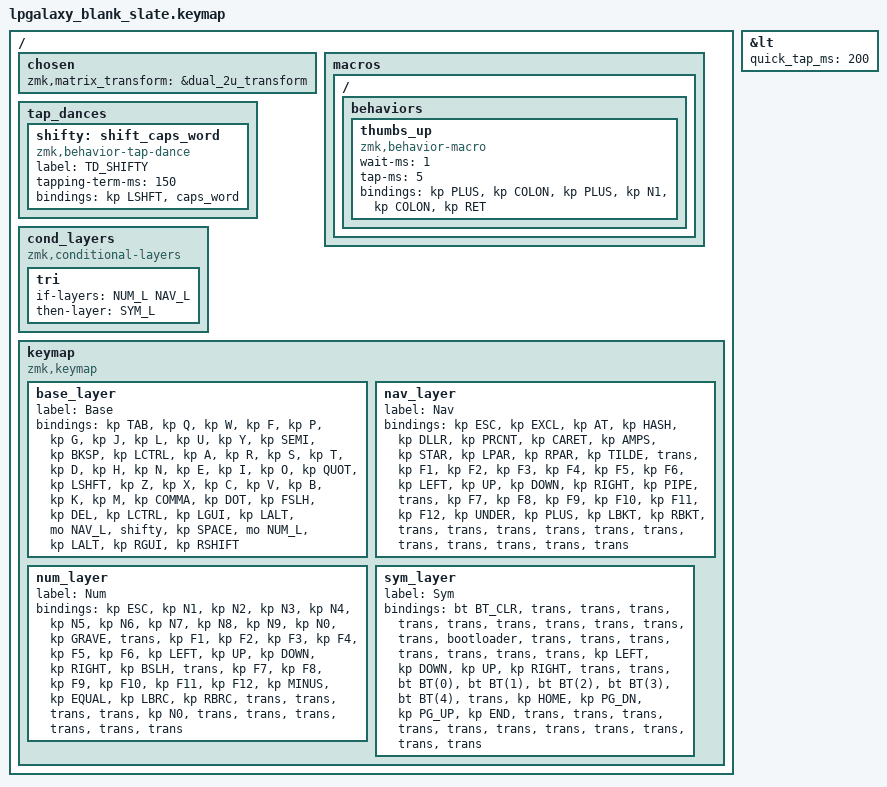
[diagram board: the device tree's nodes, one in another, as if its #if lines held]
/*
 * Copyright (c) 2022 Pete Johanson
 *
 * SPDX-License-Identifier: MIT
 */

#include <behaviors.dtsi>
#include <dt-bindings/zmk/keys.h>
#include <dt-bindings/zmk/bt.h>
#include <dt-bindings/zmk/outputs.h>

#define QWERTY_BASE 1

#define TBLE_ORTHO   1
// #define TBLE_MIT     1
// #define TBLE_DUAL_2U 1

#define NAV_L 1
#define NUM_L 2
#define SYM_L 3

// Using layer taps on thumbs, having quick tap as well helps w/ repeating space/backspace
&lt { quick_tap_ms = <200>; };

#define BT(n) BT_SEL n

/ {
    chosen {
       zmk,matrix_transform =
#ifdef TBLE_DUAL_2U
                       &dual_2u_transform;
#elif defined(TBLE_MIT)
                       &mit_transform;
#else
                       &ortho_transform;
#endif
    };

    macros {
      ZMK_MACRO(thumbs_up,
		wait-ms = <1>;
		tap-ms = <5>;
                bindings = <&kp PLUS &kp COLON &kp PLUS &kp N1 &kp COLON &kp RET>;
		)
    };
    
    tap_dances {
    	shifty: shift_caps_word {
		compatible = "zmk,behavior-tap-dance";
		label = "TD_SHIFTY";
		#binding-cells = <0>;
		tapping-term-ms = <150>;
		bindings = <&kp LSHFT>, <&caps_word>;
	};
    };

// Conditional layer only when we have less thumb keys
#ifdef TBLE_DUAL_2U
    cond_layers {
        compatible = "zmk,conditional-layers";
	tri {
	    if-layers = <NUM_L NAV_L>;
	    then-layer = <SYM_L>;
        };
    };
#endif

    keymap {
        compatible = "zmk,keymap";

        base_layer {
            label = "Base";
            bindings = <
#ifdef QWERTY_BASE
 &kp TAB    &kp Q      &kp W      &kp F       &kp P          &kp G          &kp J            &kp L          &kp U       &kp Y      &kp SEMI      &kp BKSP
 &kp LCTRL  &kp A      &kp R      &kp S       &kp T          &kp D          &kp H            &kp N          &kp E       &kp I      &kp O         &kp QUOT
 &kp LSHFT  &kp Z      &kp X      &kp C       &kp V          &kp B          &kp K            &kp M          &kp COMMA   &kp DOT    &kp FSLH      &kp DEL
#else
 &kp TAB    &kp Q      &kp W      &kp E       &kp R          &kp T          &kp Y            &kp U          &kp I       &kp O      &kp P         &kp BKSP
 &kp LCTRL  &kp A      &kp S      &kp D       &kp F          &kp G          &kp H            &kp J          &kp K       &kp L      &kp SEMI      &kp QUOT
 &kp LSHFT  &kp Z      &kp X      &kp C       &kp V          &kp B          &kp N            &kp M          &kp COMMA   &kp DOT    &kp FSLH      &kp DEL
#endif
#ifdef TBLE_DUAL_2U
 &kp LCTRL  &kp LGUI   &kp LALT   &mo NAV_L         &shifty                        &kp SPACE                &mo NUM_L   &kp LALT   &kp RGUI      &kp RSHIFT
#elif defined(TBLE_MIT)
 &kp LCTRL  &mo SYM_L  &kp LGUI  &kp LALT    &mo NAV_L          &kp SPACE                   &mo NUM_L      &kp LEFT    &kp UP     &kp DOWN      &kp RIGHT
#else
 &mo SYM_L  &kp LGUI   &kp LALT  &kp LALT    &mo NAV_L       &kp RET        &kp SPACE        &mo NUM_L      &kp LEFT    &kp UP     &kp DOWN      &kp RIGHT
#endif
            >;
        };

        nav_layer {
            label = "Nav";
            bindings = <
&kp ESC    &kp EXCL   &kp AT &kp HASH &kp DLLR &kp PRCNT  &kp CARET     &kp AMPS   &kp STAR    &kp LPAR     &kp RPAR    &kp TILDE
&trans     &kp F1     &kp F2 &kp F3 &kp F4    &kp F5      &kp F6        &kp LEFT   &kp UP      &kp DOWN     &kp RIGHT   &kp PIPE
&trans     &kp F7     &kp F8 &kp F9 &kp F10   &kp F11     &kp F12       &kp UNDER  &kp PLUS    &kp LBKT     &kp RBKT    &trans
#ifdef TBLE_DUAL_2U
&trans  &trans        &trans     &trans              &trans                    &trans       &trans         &trans &trans &trans
#elif defined(TBLE_MIT)
&trans  &trans        &trans     &trans      &trans                &trans             &trans      &trans   &trans &trans &trans
#else
&trans  &trans        &trans     &trans      &trans          &trans       &trans    &trans  &trans         &trans &trans &trans
#endif
            >;
        };

        num_layer {
            label = "Num";
            bindings = <
&kp ESC    &kp N1     &kp N2 &kp N3 &kp N4    &kp N5      &kp N6        &kp N7     &kp N8      &kp N9       &kp N0     &kp GRAVE
&trans     &kp F1     &kp F2 &kp F3 &kp F4    &kp F5      &kp F6        &kp LEFT   &kp UP      &kp DOWN     &kp RIGHT  &kp BSLH
&trans     &kp F7     &kp F8 &kp F9 &kp F10   &kp F11     &kp F12       &kp MINUS  &kp EQUAL   &kp LBRC     &kp RBRC   &trans
#ifdef TBLE_DUAL_2U
&trans  &trans       &trans     &kp N0              &trans                 &trans            &trans         &trans &trans &trans
#elif defined(TBLE_MIT)
&trans  &trans       &trans     &kp N0      &trans           &none            &trans        &kp DEL      &trans &trans &trans
#else
&trans  &trans       &trans     &kp N0      &trans    &none         &none     &kp ESC        &kp DEL      &trans &trans &trans
#endif
            >;
        };

        sym_layer {
            label = "Sym";
            bindings = <
&bt BT_CLR &trans     &trans     &trans      &trans       &trans       &trans     &trans    &trans       &trans       &trans     &bootloader
&trans     &trans     &trans     &trans      &trans          &trans       &trans     &kp LEFT       &kp DOWN    &kp UP     &kp RIGHT  &trans
&trans     &bt BT(0)  &bt BT(1)  &bt BT(2)   &bt BT(3)       &bt BT(4)    &trans     &kp HOME       &kp PG_DN   &kp PG_UP  &kp END    &trans
#ifdef TBLE_DUAL_2U
&trans  &trans        &trans     &trans              &trans                    &trans       &trans         &trans &trans &trans
#elif defined(TBLE_MIT)
&trans  &trans        &trans     &trans      &trans                &trans             &trans      &trans   &trans &trans &trans
#else
&trans  &trans        &trans     &trans      &trans          &trans       &trans    &trans  &trans         &trans &trans &trans
#endif
            >;
        };


    };
};

